# R7KA8D2AD register map
Vendor: Renesas Electronics Corporation; Series: RA8; File version: 1.10.02
CPU: CM85 r0p2, little endian, MPU, FPU, VTOR, 4 interrupt priority bits, 96 interrupts
Registers are 32-bit, read-write, reset 0x0 unless marked. A register's access mark holds for its fields unless they carry their own. Offsets are from the block's base; [hi:lo] are bit positions; {n}, {i} and the like mark numbered series.

## ESWM — Layer 3 Ethernet Switch Module
Base 0x403C8000
Same registers: ESWM_NS 0x503C8000
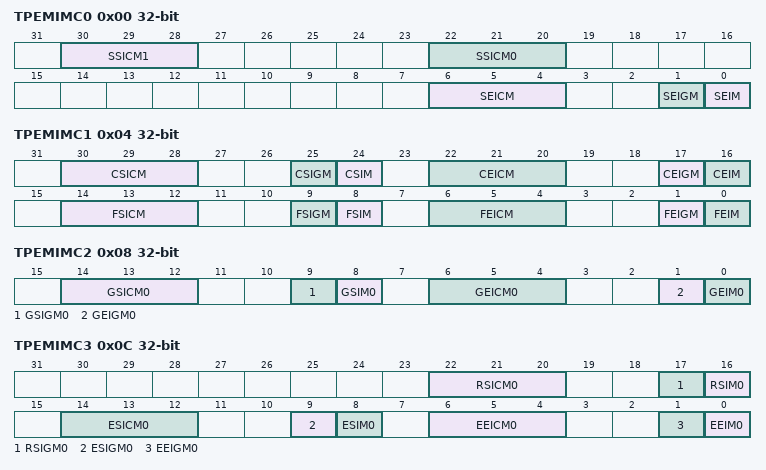
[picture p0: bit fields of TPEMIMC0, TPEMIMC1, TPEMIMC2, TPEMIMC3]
0x00 TPEMIMC0 — Error and Monitoring Interrupt Mapping Configuration Register 0
  [30:28] SSICM1 — Summarized Status Interrupt 1 Core Mapping
  [22:20] SSICM0 — Summarized Status Interrupt 0 Core Mapping
  [6:4] SEICM — Summarized Error Interrupt Core Mapping
  [1] SEIGM — Switch Error Interrupt GWCA Mapping
    0=When TPEMIMC0.SEIM is set to 1, Switch Error Interrupt is mapped to race_gwca0_core_int[TPEMIMC0.SEICM]; 1=Setting prohibited
  [0] SEIM — Summarized Error Interrupt Mapping
    0=Summarized Error Interrupt is mapped to race_race_error_int; 1=Summarized Error Interrupt is mapped to a specific core depending on TPEMIMC0.SEIGM register
0x04 TPEMIMC1 — Error and Monitoring Interrupt Mapping Configuration Register 1
  [30:28] CSICM — COMA Status Interrupt Core Mapping
  [25] CSIGM — COMA Status Interrupt GWCA Mapping
    0=When TPEMIMC1.CSIM is set to 1, COMA Status Interrupt is mapped to race_gwca0_core_int[TPEMIMC1.CSICM]; 1=Setting prohibited
  [24] CSIM — COMA Status Interrupt Mapping
    0=COMA Status Interrupt is mapped to race_coma_status_int; 1=COMA Status Interrupt is mapped to a specific core depending on TPEMIMC1.CSIGM register
  [22:20] CEICM — COMA Error Interrupt Core Mapping
  [17] CEIGM — COMA Error Interrupt GWCA Mapping
    0=When TPEMIMC1.CEIM is set to 1, COMA Error Interrupt is mapped to race_gwca0_core_int[TPEMIMC1.CEICM]; 1=Setting prohibited
  [16] CEIM — COMA Error Interrupt Mapping
    0=COMA Error Interrupt is mapped to race_coma_error_int; 1=COMA Error Interrupt is mapped to a specific core depending on TPEMIMC1.CEIGM register
  [14:12] FSICM — MFWD Status Interrupt Core Mapping
  [9] FSIGM — MFWD Status Interrupt GWCA Mapping
    0=When TPEMIMC1.FSIM is set to 1, MFWD Status Interrupt is mapped to race_gwca0_core_int[TPEMIMC1.FSICM]; 1=Setting prohibited
  [8] FSIM — MFWD Status Interrupt Mapping
    0=MFWD Status Interrupt is mapped to race_mfwd_status_int; 1=MFWD Status Interrupt is mapped to a specific core depending on TPEMIMC1.FSIGM register
  [6:4] FEICM — MFWD Error Interrupt Core Mapping
  [1] FEIGM — MFWD Error Interrupt GWCA Mapping
    0=When TPEMIMC1.FEIM is set to 1, MFWD Error Interrupt is mapped to race_gwca0_core_int[TPEMIMC1.FEICM]; 1=Setting prohibited
  [0] FEIM — MFWD Error Interrupt Mapping
    0=MFWD Error Interrupt is mapped to race_mfwd_error_int; 1=MFWD Error Interrupt is mapped to a specific core depending on TPEMIMC1.FEIGM register
0x08 TPEMIMC2 — Error and Monitoring Interrupt Mapping Configuration Register 2
  [14:12] GSICM0 — GWCA0 Status Interrupt Core Mapping
  [9] GSIGM0 — GWCA0 Status Interrupt GWCA Mapping
    0=When TPEMIMC2.GSIM0 is set to 1, GWCA0 Status Interrupt is mapped to race_gwca0_core_int[TPEMIMC2.GSICM0]; 1=Setting prohibited
  [8] GSIM0 — GWCA0 Status Interrupt Mapping
    0=GWCA0 Status Interrupt is mapped to race_ gwca0_status_int; 1=GWCA0 Status Interrupt is mapped to a specific core depending on TPEMIMC2.GSIGM0 register
  [6:4] GEICM0 — GWCA0 Error Interrupt Core Mapping
  [1] GEIGM0 — GWCA0 Error Interrupt GWCA Mapping
    0=When TPEMIMC2.GEIM0 is set to 1, GWCA0 Error Interrupt is mapped to race_gwca0_core_int[TPEMIMC2.GEICM0]; 1=Setting prohibited
  [0] GEIM0 — GWCA0 Error Interrupt Mapping
    0=GWCA0 Error Interrupt is mapped to race_ gwca0_error_int; 1=GWCA0 Error Interrupt is mapped to a specific core depending on TPEMIMC2.GEIGM0 register
0x0C TPEMIMC3 — Error and Monitoring Interrupt Mapping Configuration Register 3
  [22:20] RSICM0 — RMAC0 Status Interrupt Core Mapping
  [17] RSIGM0 — RMAC0 Status Interrupt GWCA Mapping
    0=When TPEMIMC3.RSIM0 is set to 1, RMAC0 Status Interrupt is mapped to race_gwca0_core_int[TPEMIMC3.RSICM0]; 1=Setting prohibited
  [16] RSIM0 — RMAC0 Status Interrupt Mapping
    0=RMAC0 Status Interrupt is mapped to race_rmac0_status_int; 1=RMAC0 Status Interrupt is mapped to a specific core depending on TPEMIMC3.RSIGM0 register
  [14:12] ESICM0 — ETHA0 Status Interrupt Core Mapping
  [9] ESIGM0 — ETHA0 Status Interrupt GWCA Mapping
    0=When TPEMIMC3.ESIM0 is set to 1, ETHA0 Status Interrupt is mapped to race_gwca0_core_int[TPEMIMC3.ESICM0]; 1=Setting prohibited
  [8] ESIM0 — ETHA0 Status Interrupt Mapping
    0=ETHA0 Status Interrupt is mapped to race_etha0_status_int; 1=ETHA0 Status Interrupt is mapped to a specific core depending on TPEMIMC3.ESIGM0 register
  [6:4] EEICM0 — ETHA0 Error Interrupt Core Mapping
  [1] EEIGM0 — ETHA0 Error Interrupt GWCA Mapping
    0=When TPEMIMC3.EEIM0 is set to 1, ETHA0 Error Interrupt is mapped to race_gwca0_core_int[TPEMIMC3.EEICM0]; 1=Setting prohibited
  [0] EEIM0 — ETHA0 Error Interrupt Mapping
    0=ETHA0 Error Interrupt is mapped to race_ etha0_error_int; 1=ETHA0 Error Interrupt is mapped to a specific core depending on TPEMIMC3.EEIGM0 register
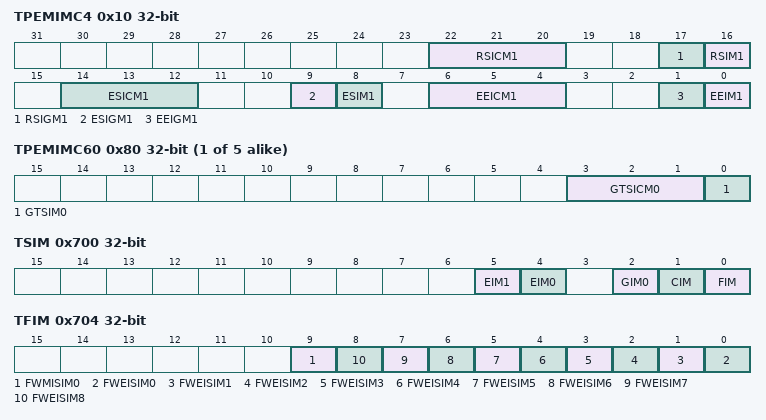
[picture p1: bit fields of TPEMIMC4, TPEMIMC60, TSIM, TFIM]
0x10 TPEMIMC4 — Error and Monitoring Interrupt Mapping Configuration Register 4
  [22:20] RSICM1 — RMAC1 Status Interrupt Core Mapping
  [17] RSIGM1 — RMAC1 Status Interrupt GWCA Mapping
    0=When TPEMIMC4.RSIM1 is set to 1, RMAC1 Status Interrupt is mapped to race_gwca0_core_int[TPEMIMC4.RSICM1]; 1=Setting prohibited
  [16] RSIM1 — RMAC1 Status Interrupt Mapping
    0=RMAC1 Status Interrupt is mapped to race_ rmac1_status_int; 1=RMAC1 Status Interrupt is mapped to a specific core depending on TPEMIMC4.RSIGM1 register
  [14:12] ESICM1 — ETHA1 Status Interrupt Core Mapping
  [9] ESIGM1 — ETHA1 Status Interrupt GWCA Mapping
    0=When TPEMIMC4.ESIM1 is set to 1, ETHA1 Status Interrupt is mapped to race_gwca0_core_int[TPEMIMC4.ESICM1]; 1=Setting prohibited
  [8] ESIM1 — ETHA1 Status Interrupt Mapping
    0=ETHA1 Status Interrupt is mapped to race_ etha1_status_int; 1=ETHA1 Status Interrupt is mapped to a specific core depending on TPEMIMC4.ESIGM1 register
  [6:4] EEICM1 — ETHA1 Error Interrupt Core Mapping
  [1] EEIGM1 — ETHA1 Error Interrupt GWCA Mapping
    0=When TPEMIMC4.EEIM1 is set to 1, ETHA1 Error Interrupt is mapped to race_gwca0_core_int[TPEMIMC4.EEICM1]; 1=Setting prohibited
  [0] EEIM1 — ETHA1 Error Interrupt Mapping
    0=ETHA1 Error Interrupt is mapped to race_ etha1_error_int; 1=ETHA1 Error Interrupt is mapped to a specific core depending on TPEMIMC4.EEIGM1 register
{0x80+4i} TPEMIMC6{i} (i=0..4) — Error and Monitoring Interrupt Mapping Configuration Register 6{i}
  [3:1] GTSICM0 — GWCA0 Timestamp Interrupt Core Mapping
  [0] GTSIM0 — GWCA0 Timestamp Interrupt Mapping
    0=GWCA0 Timestamp Interrupt t is mapped to race_gwca0_timer_int[t]; 1=GWCA0 Timestamp Interrupt t is mapped to race_gwca0_core_int depending on TPEMIMC6t.GTSICM0 setting
{0x100+4i} TPEMIMC7{i} (i=0..4) — Error and Monitoring Interrupt Mapping Configuration Register 7{i}
  [2:0] GDICM0 — GWCA0 Data Interrupt Core Mapping
0x700 TSIM ro — Summarized Interrupt Mirroring Register
  [5] EIM1 — ETHA1 Interrupt Monitoring
    0=No interrupt is set in ETHA1; 1=An interrupt is set in ETHA1
  [4] EIM0 — ETHA0 Interrupt Monitoring
    0=No interrupt is set in ETHA0; 1=An interrupt is set in ETHA0
  [2] GIM0 — GWCA0 Interrupt Monitoring
    0=No interrupt is set in GWCA0; 1=An interrupt is set in GWCA0
  [1] CIM — COMA Interrupt Mirroring
    0=No interrupt is set in COMA agent; 1=An interrupt is set in COMA agent
  [0] FIM — MFWD Interrupt Mirroring
    0=No interrupt is set in MFWD; 1=An interrupt is set in MFWD
0x704 TFIM ro — MFWD Interrupt Mirroring Register
  [9] FWMISIM0 — FWMIS0 Interrupt Mirroring
    0=No interrupt is set in forwarding engine FWMIS0 register; 1=An interrupt is set in forwarding engine FWMIS0 register
  [n] FWEISIM{n} (n=0..8) — FWEIS{n} Interrupt Mirroring
    0=No interrupt is set in forwarding engine FWEIS{n} register; 1=An interrupt is set in forwarding engine FWEIS{n} register
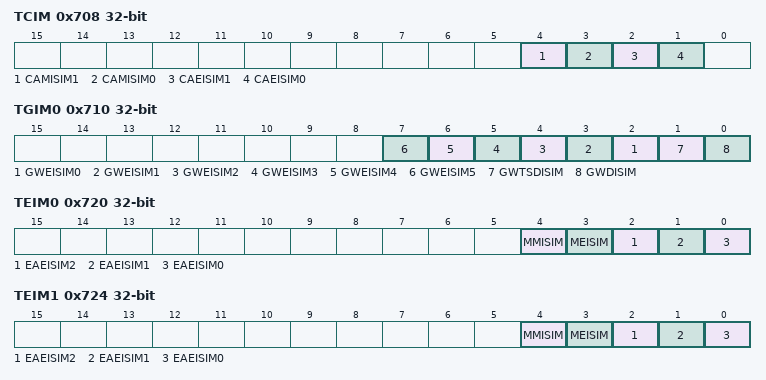
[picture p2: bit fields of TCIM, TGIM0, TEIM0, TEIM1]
0x708 TCIM ro — COMA Interrupt Mirroring Register
  [4] CAMISIM1 — CAMIS1 Interrupt Mirroring
    0=No interrupt is set in COMA agent CAMIS1 register; 1=An interrupt is set in COMA agent CAMIS1 register
  [3] CAMISIM0 — CAMIS0 Interrupt Mirroring
    0=No interrupt is set in COMA agent CAMIS0 register; 1=An interrupt is set in COMA agent CAMIS0 register
  [2] CAEISIM1 — CAEIS1 Interrupt Mirroring
    0=No interrupt is set in COMA agent CAEIS1 register; 1=An interrupt is set in COMA agent CAEIS1 register
  [1] CAEISIM0 — CAEIS0 Interrupt Mirroring
    0=No interrupt is set in COMA agent CAEIS0 register; 1=An interrupt is set in COMA agent CAEIS0 register
0x710 TGIM0 ro — GWCA0 Interrupt Mirroring Register
  [n+2] GWEISIM{n} (n=0..5) — GWEIS{n} Interrupt Mirroring
    0=No interrupt is set in GWCA0 GWEIS{n} register; 1=An interrupt is set in GWCA0 GWEIS{n} register
  [1] GWTSDISIM — GWTSDIS Interrupt Mirroring
    0=No interrupt is set in GWCA0 GWTSDIS register; 1=An interrupt is set in GWCA0 GWTSDIS register
  [0] GWDISIM — GWDIS Interrupt Mirroring
    0=No interrupt is set in GWCA0 GWDIS register; 1=An interrupt is set in GWCA0 GWDIS register
0x720 TEIM0 ro — ETHA0 Interrupt Mirroring Register
  [4] MMISIM — MMIS0 Interrupt Mirroring
    0=No interrupt is set in ETHA0 RMAC MMIS0 register; 1=An interrupt is set in ETHA0 RMAC MMIS0 register
  [3] MEISIM — MEIS Interrupt Mirroring
    0=No interrupt is set in ETHA0 RMAC MEIS register; 1=An interrupt is set in ETHA0 RMAC MEIS register
  [2] EAEISIM2 — EAEIS2 Interrupt Mirroring
    0=No interrupt is set in ETHA0 EAEIS2 register; 1=An interrupt is set in ETHA0 EAEIS2 register
  [1] EAEISIM1 — EAEIS1 Interrupt Mirroring
    0=No interrupt is set in ETHA0 EAEIS1 register; 1=An interrupt is set in ETHA0 EAEIS1 register
  [0] EAEISIM0 — EAEIS0 Interrupt Mirroring
    0=No interrupt is set in ETHA0 EAEIS0 register; 1=An interrupt is set in ETHA0 EAEIS0 register
0x724 TEIM1 ro — ETHA1 Interrupt Mirroring Register
  [4] MMISIM — MMIS0 Interrupt Mirroring
    0=No interrupt is set in ETHA1 RMAC MMIS0 register; 1=An interrupt is set in ETHA1 RMAC MMIS0 register
  [3] MEISIM — MEIS Interrupt Mirroring
    0=No interrupt is set in ETHA1 RMAC MEIS register; 1=An interrupt is set in ETHA1 RMAC MEIS register
  [2] EAEISIM2 — EAEIS2 Interrupt Mirroring
    0=No interrupt is set in ETHA1 EAEIS2 register; 1=An interrupt is set in ETHA1 EAEIS2 register
  [1] EAEISIM1 — EAEIS1 Interrupt Mirroring
    0=No interrupt is set in ETHA1 EAEIS1 register; 1=An interrupt is set in ETHA1 EAEIS1 register
  [0] EAEISIM0 — EAEIS0 Interrupt Mirroring
    0=No interrupt is set in ETHA1 EAEIS0 register; 1=An interrupt is set in ETHA1 EAEIS0 register
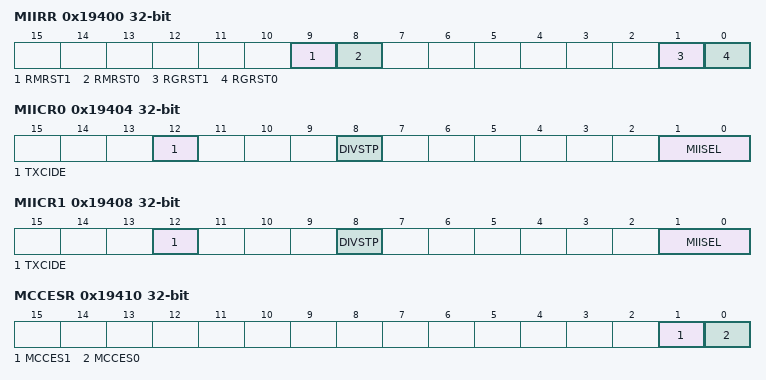
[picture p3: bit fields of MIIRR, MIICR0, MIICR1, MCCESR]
0x19400 MIIRR — Media-independent Interface Reset Register
  [all] fields
    0=Reset; 1=Enable
  [9] RMRST1 — RMII1 Reset
  [8] RMRST0 — RMII0 Reset
  [1] RGRST1 — RGMII1 Reset
  [0] RGRST0 — RGMII0 Reset
0x19404 MIICR0 — Media-independent Interface Control Register 0
  [12] TXCIDE — RGMII TXC Internal Delay Enable
    0=TXC internal delay disable; 1=TXC internal delay enable
  [8] DIVSTP — Clock Divider Stop
    0=Enable; 1=Stop
  [1:0] MIISEL — Media-independent Interface Select
    0=MII/GMII; 1=RGMII; 2=RMII; 3=Setting prohibited
0x19408 MIICR1 — Media-independent Interface Control Register 1
  [12] TXCIDE — RGMII TXC Internal Delay Enable
    0=TXC Internal delay disable; 1=TXC Internal delay enable
  [8] DIVSTP — Clock Divider Stop
    0=Enable; 1=Stop
  [1:0] MIISEL — Media-independent Interface Select
    0=MII/GMII; 1=RGMII; 2=RMII; 3=Setting prohibited
0x19410 MCCESR — Media Clock Capture Event Select Register
  [1] MCCES1 — Media Clock 1 Capture Event Select
    0=I/O Port; 1=ELC
  [0] MCCES0 — Media Clock 0 Capture Event Select
    0=I/O Port; 1=ELC
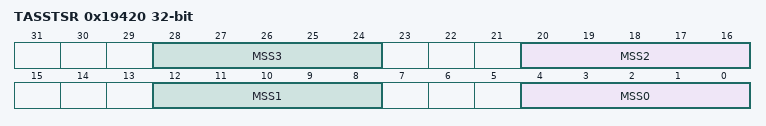
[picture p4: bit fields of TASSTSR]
0x19420 TASSTSR — TAS Status Monitor Signal Select Register
  [8n+4:8n] MSS{n} (n=0..3) — ET_TAS_STA{n} Monitor Signal Select
